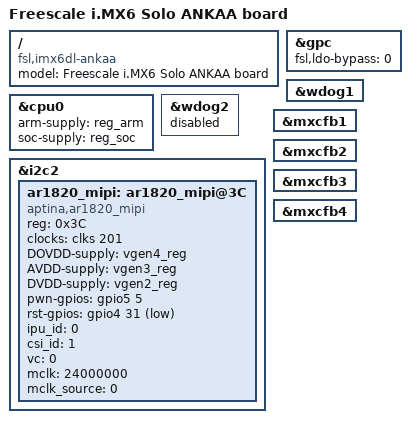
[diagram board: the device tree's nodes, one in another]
/*
 * Copyright (C) 2015 Freescale Semiconductor, Inc.
 *
 * This program is free software; you can redistribute it and/or modify
 * it under the terms of the GNU General Public License version 2 as
 * published by the Free Software Foundation.
 */

/dts-v1/;

#include "imx6s.dtsi"
#include "imx6qdl-esomimx6-re-test.dtsi"

/ {
	model = "Freescale i.MX6 Solo ANKAA board";
	compatible = "fsl,imx6dl-ankaa", "fsl,imx6dl";
};

&cpu0 {
	arm-supply = <&reg_arm>;
	soc-supply = <&reg_soc>;
};

&gpc {
	/* use ldo-enable, u-boot will check it and configure */
	fsl,ldo-bypass = <0>;
};

&wdog1 {
	status = "okay";
};

&wdog2 {
	status = "disabled";
};

/* ar1820 camera module */
&i2c2 {
        ar1820_mipi: ar1820_mipi@3C {
                compatible = "aptina,ar1820_mipi";
		reg = <0x3C>;
                clocks = <&clks 201>;
                clock-names = "csi_mclk";
                DOVDD-supply = <&vgen4_reg>; /* 1.8v */
                AVDD-supply = <&vgen3_reg>;  /* 2.8v, rev C board is VGEN3
                                                rev B board is VGEN5 */
                DVDD-supply = <&vgen2_reg>;  /* 1.5v*/
                pwn-gpios = <&gpio5 5 0>;   /* active high: DISP_DATA11 but it is not used by the camera module*/
                rst-gpios = <&gpio4 31 1>;   /* active low: DISP_DATA10 */
                ipu_id = <0>;
                csi_id = <1>;
                vc = <0>;
                mclk = <24000000>;
                mclk_source = <0>;
                status="okay";
        };

};

&mxcfb1 {
	status = "okay";
};

&mxcfb2 {
	status = "okay";
};

&mxcfb3 {
	status = "okay";
};

&mxcfb4 {
	status = "okay";
};

